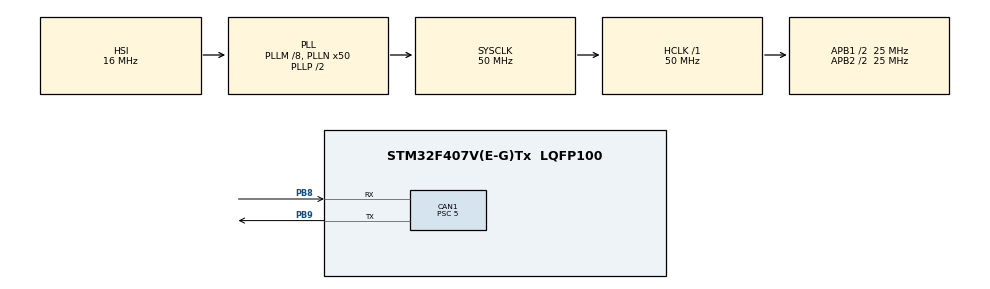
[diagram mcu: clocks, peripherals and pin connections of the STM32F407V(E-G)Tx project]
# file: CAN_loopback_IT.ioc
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CAN1.BS1=CAN_BS1_8TQ
CAN1.CalculateBaudRate=500000
CAN1.CalculateTimeBit=2000
CAN1.CalculateTimeQuantum=200.0
CAN1.Mode=CAN_MODE_LOOPBACK
CAN1.NART=ENABLE
CAN1.Prescaler=5
Mcu.Family=STM32F4
Mcu.Name=STM32F407V(E-G)Tx
Mcu.Package=LQFP100
NVIC.CAN1_RX0_IRQn=true\:0\:0\:false\:false\:true\:true\:true\:true
NVIC.CAN1_RX1_IRQn=true\:0\:0\:false\:false\:true\:true\:true\:true
NVIC.CAN1_TX_IRQn=true\:0\:0\:false\:false\:true\:true\:true\:true
NVIC.PriorityGroup=NVIC_PRIORITYGROUP_0
PB8.Mode=CAN_Activate
PB8.Signal=CAN1_RX
PB9.Mode=CAN_Activate
PB9.Signal=CAN1_TX
PH0-OSC_IN.Mode=HSE-External-Oscillator
PH0-OSC_IN.Signal=RCC_OSC_IN
PH1-OSC_OUT.Mode=HSE-External-Oscillator
PH1-OSC_OUT.Signal=RCC_OSC_OUT
ProjectManager.HeapSize=0x200
ProjectManager.StackSize=0x400
ProjectManager.TargetToolchain=STM32CubeIDE
RCC.48MHZClocksFreq_Value=14285714.285714285
RCC.AHBFreq_Value=50000000
RCC.APB1CLKDivider=RCC_HCLK_DIV2
RCC.APB1Freq_Value=25000000
RCC.APB1TimFreq_Value=50000000
RCC.APB2CLKDivider=RCC_HCLK_DIV2
RCC.APB2Freq_Value=25000000
RCC.APB2TimFreq_Value=50000000
RCC.CortexFreq_Value=50000000
RCC.HCLKFreq_Value=50000000
RCC.HSE_VALUE=8000000
RCC.HSI_VALUE=16000000
RCC.LSE_VALUE=32768
RCC.PLLM=8
RCC.PLLN=50
RCC.PLLQ=7
RCC.SYSCLKFreq_VALUE=50000000
RCC.SYSCLKSource=RCC_SYSCLKSOURCE_PLLCLK
RCC.VCOOutputFreq_Value=100000000
board=STM32F407G-DISC1

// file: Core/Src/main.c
/* USER CODE BEGIN Header */
/**
  ******************************************************************************
  * @file           : main.c
  * @brief          : Main program body
  ******************************************************************************
  * @attention
  *
  * Copyright (c) 2025 STMicroelectronics.
  * All rights reserved.
  *
  * This software is licensed under terms that can be found in the LICENSE file
  * in the root directory of this software component.
  * If no LICENSE file comes with this software, it is provided AS-IS.
  *
  ******************************************************************************
  */
/* USER CODE END Header */
#include "main.h"

/* USER CODE BEGIN Includes */
#include <stdio.h>
/* USER CODE END Includes */

CAN_HandleTypeDef hcan1;

void SystemClock_Config(void);
static void MX_GPIO_Init(void);
static void MX_CAN1_Init(void);
/* USER CODE BEGIN PFP */
void CAN1_Tx(void);
//void CAN1_Rx(void);

void CAN_Filter_Config(void);

/* USER CODE END PFP */

/* USER CODE BEGIN 0 */
void HAL_CAN_TxMailbox0CompleteCallback(CAN_HandleTypeDef *hcan)
{
	printf("message transmitted : M0 \r\n");
}
void HAL_CAN_TxMailbox1CompleteCallback(CAN_HandleTypeDef *hcan)
{
	printf("message transmitted : M1 \r\n");
}
void HAL_CAN_TxMailbox2CompleteCallback(CAN_HandleTypeDef *hcan)
{
	printf("message transmitted : M2 \r\n");
}

void HAL_CAN_RxFifo0MsgPendingCallback(CAN_HandleTypeDef *hcan)
{
	CAN_RxHeaderTypeDef RxHeader;

	uint8_t rcvd_msg[5];

	if (HAL_CAN_GetRxMessage(&hcan1, CAN_RX_FIFO0, &RxHeader, rcvd_msg ) != HAL_OK)
	{
		Error_Handler();
	}

	printf("message received : %s\n", rcvd_msg);

}

void HAL_CAN_ErrorCallback(CAN_HandleTypeDef *hcan)
{
	printf("CAN error !");
	Error_Handler();
}
/* USER CODE END 0 */

int main(void)
{

  /* MCU Configuration--------------------------------------------------------*/

  /* Reset of all peripherals, Initializes the Flash interface and the Systick. */
  HAL_Init();

  /* Configure the system clock */
  SystemClock_Config();

  /* Initialize all configured peripherals */
  MX_GPIO_Init();
  MX_CAN1_Init();
  /* USER CODE BEGIN 2 */
  CAN_Filter_Config();

  if (HAL_CAN_ActivateNotification(&hcan1, CAN_IT_TX_MAILBOX_EMPTY | CAN_IT_RX_FIFO0_MSG_PENDING | CAN_IT_BUSOFF) != HAL_OK)
  {
	  Error_Handler();
  }

  if (HAL_CAN_Start(&hcan1) != HAL_OK)
  {
	  Error_Handler();
  }

  CAN1_Tx();

  /* USER CODE END 2 */

  /* Infinite loop */
  while (1)
  {

  }
}

void SystemClock_Config(void)
{
  RCC_OscInitTypeDef RCC_OscInitStruct = {0};
  RCC_ClkInitTypeDef RCC_ClkInitStruct = {0};

  /** Configure the main internal regulator output voltage
  */
  __HAL_RCC_PWR_CLK_ENABLE();
  __HAL_PWR_VOLTAGESCALING_CONFIG(PWR_REGULATOR_VOLTAGE_SCALE1);

  /** Initializes the RCC Oscillators according to the specified parameters
  * in the RCC_OscInitTypeDef structure.
  */
  RCC_OscInitStruct.OscillatorType = RCC_OSCILLATORTYPE_HSI;
  RCC_OscInitStruct.HSIState = RCC_HSI_ON;
  RCC_OscInitStruct.HSICalibrationValue = RCC_HSICALIBRATION_DEFAULT;
  RCC_OscInitStruct.PLL.PLLState = RCC_PLL_ON;
  RCC_OscInitStruct.PLL.PLLSource = RCC_PLLSOURCE_HSI;
  RCC_OscInitStruct.PLL.PLLM = 8;
  RCC_OscInitStruct.PLL.PLLN = 50;
  RCC_OscInitStruct.PLL.PLLP = RCC_PLLP_DIV2;
  RCC_OscInitStruct.PLL.PLLQ = 7;
  if (HAL_RCC_OscConfig(&RCC_OscInitStruct) != HAL_OK)
  {
    Error_Handler();
  }

  /** Initializes the CPU, AHB and APB buses clocks
  */
  RCC_ClkInitStruct.ClockType = RCC_CLOCKTYPE_HCLK|RCC_CLOCKTYPE_SYSCLK
                              |RCC_CLOCKTYPE_PCLK1|RCC_CLOCKTYPE_PCLK2;
  RCC_ClkInitStruct.SYSCLKSource = RCC_SYSCLKSOURCE_PLLCLK;
  RCC_ClkInitStruct.AHBCLKDivider = RCC_SYSCLK_DIV1;
  RCC_ClkInitStruct.APB1CLKDivider = RCC_HCLK_DIV2;
  RCC_ClkInitStruct.APB2CLKDivider = RCC_HCLK_DIV2;

  if (HAL_RCC_ClockConfig(&RCC_ClkInitStruct, FLASH_LATENCY_1) != HAL_OK)
  {
    Error_Handler();
  }
}

static void MX_CAN1_Init(void)
{

  hcan1.Instance = CAN1;
  hcan1.Init.Prescaler = 5;
  hcan1.Init.Mode = CAN_MODE_LOOPBACK;
  hcan1.Init.SyncJumpWidth = CAN_SJW_1TQ;
  hcan1.Init.TimeSeg1 = CAN_BS1_8TQ;
  hcan1.Init.TimeSeg2 = CAN_BS2_1TQ;
  hcan1.Init.TimeTriggeredMode = DISABLE;
  hcan1.Init.AutoBusOff = DISABLE;
  hcan1.Init.AutoWakeUp = DISABLE;
  hcan1.Init.AutoRetransmission = ENABLE;
  hcan1.Init.ReceiveFifoLocked = DISABLE;
  hcan1.Init.TransmitFifoPriority = DISABLE;
  if (HAL_CAN_Init(&hcan1) != HAL_OK)
  {
    Error_Handler();
  }

}

static void MX_GPIO_Init(void)
{

  /* GPIO Ports Clock Enable */
  __HAL_RCC_GPIOH_CLK_ENABLE();
  __HAL_RCC_GPIOB_CLK_ENABLE();

}

/* USER CODE BEGIN 4 */
void CAN1_Tx (void)
{
	CAN_TxHeaderTypeDef TxHeader ;

	uint32_t TxMailbox;

	uint8_t our_message[5] = {'H', 'E', 'L', 'L', 'O'};

	TxHeader.DLC = 5;
	TxHeader.StdId = 0x65D;
	TxHeader.IDE = CAN_ID_STD;
	TxHeader.RTR = CAN_RTR_DATA;

	if (HAL_CAN_AddTxMessage(&hcan1, &TxHeader, our_message, &TxMailbox) != HAL_OK)
	{
		Error_Handler();
	}

}

/*
void CAN1_Rx(void)
{
	CAN_RxHeaderTypeDef RxHeader;

	uint8_t rcvd_msg[5];

	// we waiting for at least one message in to the RX FIFO0
	while ( ! HAL_CAN_GetRxFifoFillLevel(&hcan1, CAN_RX_FIFO0));

	if (HAL_CAN_GetRxMessage(&hcan1, CAN_RX_FIFO0, &RxHeader, rcvd_msg ) != HAL_OK)
	{
		Error_Handler();
	}

	printf("message received : %s\n", rcvd_msg);
}
*/

void CAN_Filter_Config(void)
{
	CAN_FilterTypeDef can1_Filter_init;

	can1_Filter_init.FilterActivation = ENABLE ;
	can1_Filter_init.FilterBank = 0 ;
	can1_Filter_init.FilterFIFOAssignment = CAN_RX_FIFO0 ;
	can1_Filter_init.FilterIdHigh = 0x0000 ;
	can1_Filter_init.FilterIdLow = 0x0000 ;
	can1_Filter_init.FilterMaskIdHigh = 0x0000 ;
	can1_Filter_init.FilterMaskIdLow = 0x0000 ;
	can1_Filter_init.FilterMode = CAN_FILTERMODE_IDMASK ;
	can1_Filter_init.FilterScale = CAN_FILTERSCALE_32BIT ;

	if (HAL_CAN_ConfigFilter(&hcan1, &can1_Filter_init) != HAL_OK )
	{
		Error_Handler();
	}

}
/* USER CODE END 4 */

void Error_Handler(void)
{
  __disable_irq();
  while (1)
  {
  }
}
